AUTOSAR XML (schema 00044)
package /ComponentTypes
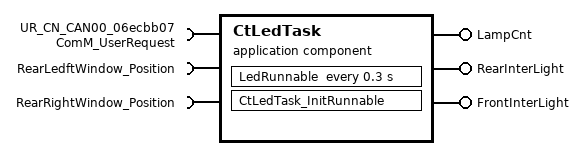
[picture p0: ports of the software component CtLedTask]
  application sw component type CtLedTask
    require port UR_CN_CAN00_06ecbb07: required-com-specs=[RequestComMode, GetCurrentComMode, GetMaxComMode, GetRequestedComMode], required-interface=ComM_UserRequest
    provide port LampCnt: nonqueued-sender-com-spec{data-element=u8_Singal, init-value=0}, provided-interface=LampCnt
    provide port RearInterLight: nonqueued-sender-com-spec{data-element=Bool_Signal, init-value=0}, provided-interface=RearInterLight
    provide port FrontInterLight: nonqueued-sender-com-spec{data-element=bool_Signal, init-value=0}, provided-interface=FrontInterLight
    require port RearLedftWindow_Position: nonqueued-receiver-com-spec{data-element=u8_Signal, init-value=0}, required-interface=RearLedftWindow_Position
    require port RearRightWindow_Position: nonqueued-receiver-com-spec{data-element=u8_Signal, init-value=0}, required-interface=RearRightWindow_Position
    behavior CtLedTask_InternalBehavior
      timing event TMT_LedRunnable: start-on-event=LedRunnable, period=0.3
      init event CtLedTask_InitEvent: start-on-event=CtLedTask_InitRunnable
      runnable LedRunnable
        data-receive-point-by-arguments:
          access REC_RearLedftWindow_Position_u8_Signal: accessed-variable=RearLedftWindow_Position.u8_Signal
          access REC_RearRightWindow_Position_u8_Signal: accessed-variable=RearRightWindow_Position.u8_Signal
        data-send-points:
          access SEND_LampCnt_u8_Singal: accessed-variable=LampCnt.u8_Singal
          access SEND_RearInterLight_Bool_Signal: accessed-variable=RearInterLight.Bool_Signal
          access SEND_FrontInterLight_bool_Signal: accessed-variable=FrontInterLight.bool_Signal
      runnable CtLedTask_InitRunnable
        4 x sync call:
          SC_UR_CN_CAN00_06ecbb07_GetCurrentComMode: operation=UR_CN_CAN00_06ecbb07.GetCurrentComMode
          SC_UR_CN_CAN00_06ecbb07_GetMaxComMode: operation=UR_CN_CAN00_06ecbb07.GetMaxComMode
          SC_UR_CN_CAN00_06ecbb07_GetRequestedComMode: operation=UR_CN_CAN00_06ecbb07.GetRequestedComMode
          SC_UR_CN_CAN00_06ecbb07_RequestComMode: operation=UR_CN_CAN00_06ecbb07.RequestComMode
  swc implementation CtLedTask_Implementation: behavior=CtLedTask_InternalBehavior
